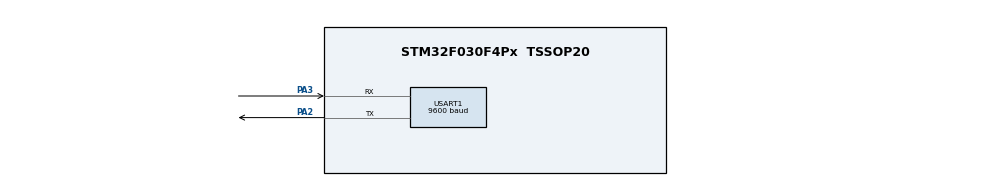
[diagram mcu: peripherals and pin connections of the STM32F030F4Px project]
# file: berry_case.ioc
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Dma.Request0=USART1_RX
Dma.USART1_RX.0.Direction=DMA_PERIPH_TO_MEMORY
Dma.USART1_RX.0.Instance=DMA1_Channel5
Dma.USART1_RX.0.MemDataAlignment=DMA_MDATAALIGN_BYTE
Dma.USART1_RX.0.MemInc=DMA_MINC_ENABLE
Dma.USART1_RX.0.Mode=DMA_NORMAL
Dma.USART1_RX.0.PeriphDataAlignment=DMA_PDATAALIGN_BYTE
Dma.USART1_RX.0.PeriphInc=DMA_PINC_DISABLE
Dma.USART1_RX.0.Priority=DMA_PRIORITY_LOW
Mcu.Family=STM32F0
Mcu.Name=STM32F030F4Px
Mcu.Package=TSSOP20
NVIC.DMA1_Channel4_5_IRQn=true\:0\:0\:false\:false\:true\:false\:true
PA13.Mode=Serial_Wire
PA13.Signal=SYS_SWDIO
PA14.Mode=Serial_Wire
PA14.Signal=SYS_SWCLK
PA2.Mode=Asynchronous
PA2.Signal=USART1_TX
PA3.Mode=Asynchronous
PA3.Signal=USART1_RX
ProjectManager.HeapSize=0x200
ProjectManager.StackSize=0x400
ProjectManager.TargetToolchain=STM32CubeIDE
USART1.BaudRate=9600
USART1.VirtualMode-Asynchronous=VM_ASYNC
board=custom

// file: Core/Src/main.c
/* USER CODE BEGIN Header */
/**
  ******************************************************************************
  * @file           : main.c
  * @brief          : Main program body
  ******************************************************************************
  * @attention
  *
  * <h2><center>&copy; Copyright (c) 2020 STMicroelectronics.
  * All rights reserved.</center></h2>
  *
  * This software component is licensed by ST under BSD 3-Clause license,
  * the "License"; You may not use this file except in compliance with the
  * License. You may obtain a copy of the License at:
  *                        opensource.org/licenses/BSD-3-Clause
  *
  ******************************************************************************
  */
/* USER CODE END Header */

#include <stm32f030x6.h>
#include <stm32f0xx_hal_cortex.h>
#include <stm32f0xx_hal_def.h>
#include <stm32f0xx_hal_dma.h>
#include <stm32f0xx_hal_flash.h>
#include <stm32f0xx_hal_rcc.h>
#include <stm32f0xx_hal_rcc_ex.h>
#include <stm32f0xx_hal_uart.h>
#include <stm32f0xx_hal_uart_ex.h>
#include "main.h"

/* USER CODE BEGIN Includes */
//#include "app.h"
/* USER CODE END Includes */

UART_HandleTypeDef huart1;
DMA_HandleTypeDef hdma_usart1_rx;

void SystemClock_Config(void);
static void MX_GPIO_Init(void);
static void MX_DMA_Init(void);
static void MX_USART1_UART_Init(void);

int main(void)
{

  /* MCU Configuration--------------------------------------------------------*/

  /* Reset of all peripherals, Initializes the Flash interface and the Systick. */
  HAL_Init();

  /* Configure the system clock */
  SystemClock_Config();

  /* Initialize all configured peripherals */
  MX_GPIO_Init();
  MX_DMA_Init();
  MX_USART1_UART_Init();

  /* Infinite loop */
  while (1)
  {

  }
}

void SystemClock_Config(void)
{
  RCC_OscInitTypeDef RCC_OscInitStruct = {0};
  RCC_ClkInitTypeDef RCC_ClkInitStruct = {0};
  RCC_PeriphCLKInitTypeDef PeriphClkInit = {0};

  /** Initializes the RCC Oscillators according to the specified parameters
  * in the RCC_OscInitTypeDef structure.
  */
  RCC_OscInitStruct.OscillatorType = RCC_OSCILLATORTYPE_HSI;
  RCC_OscInitStruct.HSIState = RCC_HSI_ON;
  RCC_OscInitStruct.HSICalibrationValue = RCC_HSICALIBRATION_DEFAULT;
  RCC_OscInitStruct.PLL.PLLState = RCC_PLL_NONE;
  if (HAL_RCC_OscConfig(&RCC_OscInitStruct) != HAL_OK)
  {
    Error_Handler();
  }
  /** Initializes the CPU, AHB and APB buses clocks
  */
  RCC_ClkInitStruct.ClockType = RCC_CLOCKTYPE_HCLK|RCC_CLOCKTYPE_SYSCLK
                              |RCC_CLOCKTYPE_PCLK1;
  RCC_ClkInitStruct.SYSCLKSource = RCC_SYSCLKSOURCE_HSI;
  RCC_ClkInitStruct.AHBCLKDivider = RCC_SYSCLK_DIV1;
  RCC_ClkInitStruct.APB1CLKDivider = RCC_HCLK_DIV1;

  if (HAL_RCC_ClockConfig(&RCC_ClkInitStruct, FLASH_LATENCY_0) != HAL_OK)
  {
    Error_Handler();
  }
  PeriphClkInit.PeriphClockSelection = RCC_PERIPHCLK_USART1;
  PeriphClkInit.Usart1ClockSelection = RCC_USART1CLKSOURCE_PCLK1;
  if (HAL_RCCEx_PeriphCLKConfig(&PeriphClkInit) != HAL_OK)
  {
    Error_Handler();
  }
}

static void MX_USART1_UART_Init(void)
{

  huart1.Instance = USART1;
  huart1.Init.BaudRate = 9600;
  huart1.Init.WordLength = UART_WORDLENGTH_8B;
  huart1.Init.StopBits = UART_STOPBITS_1;
  huart1.Init.Parity = UART_PARITY_NONE;
  huart1.Init.Mode = UART_MODE_TX_RX;
  huart1.Init.HwFlowCtl = UART_HWCONTROL_NONE;
  huart1.Init.OverSampling = UART_OVERSAMPLING_16;
  huart1.Init.OneBitSampling = UART_ONE_BIT_SAMPLE_DISABLE;
  huart1.AdvancedInit.AdvFeatureInit = UART_ADVFEATURE_NO_INIT;
  if (HAL_UART_Init(&huart1) != HAL_OK)
  {
    Error_Handler();
  }

}

static void MX_DMA_Init(void)
{

  /* DMA controller clock enable */
  __HAL_RCC_DMA1_CLK_ENABLE();

  /* DMA interrupt init */
  /* DMA1_Channel4_5_IRQn interrupt configuration */
  HAL_NVIC_SetPriority(DMA1_Channel4_5_IRQn, 0, 0);
  HAL_NVIC_EnableIRQ(DMA1_Channel4_5_IRQn);

}

static void MX_GPIO_Init(void)
{

  /* GPIO Ports Clock Enable */
  __HAL_RCC_GPIOA_CLK_ENABLE();

}

void Error_Handler(void)
{
}

/************************ (C) COPYRIGHT STMicroelectronics *****END OF FILE****/
